# EFR32MG24A420F1536IM48 register map
Vendor: Silicon Labs; Series: EFR32; File version: B
Registers are 32-bit, read-write, reset 0x0 unless marked. A register's access mark holds for its fields unless they carry their own. Offsets are from the block's base; [hi:lo] are bit positions; {n}, {i} and the like mark numbered series.

## DMEM_NS — DMEM_NS Registers
Base 0x500B4000
Same registers: DMEM_S 0x400B4000
0x00 IPVERSION ro reset 0x2
  [1:0] IPVERSION — New BitField
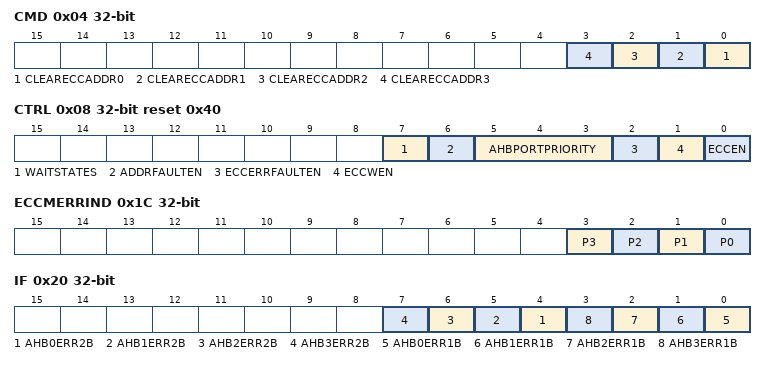
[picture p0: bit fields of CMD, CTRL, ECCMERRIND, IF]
0x04 CMD wo
  [n] CLEARECCADDR{n} (n=0..3) — Clear ECCERRADDR{n}
0x08 CTRL reset 0x40
  [7] WAITSTATES — RAM read wait states
  [6] ADDRFAULTEN — Address fault bus fault enable
  [5:3] AHBPORTPRIORITY — AHB port arbitration priority
    0=NONE (No AHB port have raised priority.); {v}=PORT{v-1} (AHB port {v-1} has raised priority.) (v=1..4)
  [2] ECCERRFAULTEN — ECC Error bus fault enable
  [1] ECCWEN — Enable ECC syndrome writes
  [0] ECCEN — Enable ECC functionality
{0xC+4i} ECCERRADDR{i} ro (i=0..3)
  [31:0] ADDR — ECC Error Address
0x1C ECCMERRIND ro
  [3] P3 — Multiple ECC errors on AHB port 2
  [2] P2 — Multiple ECC errors on AHB port 2
  [1] P1 — Multiple ECC errors on AHB port 1
  [0] P0 — Multiple ECC errors on AHB port 0
0x20 IF
  [n+4] AHB{n}ERR2B (n=0..3) — AHB{n} 2-bit ECC Error Interrupt Flag
  [n] AHB{n}ERR1B (n=0..3) — AHB{n} 1-bit ECC Error Interrupt Flag
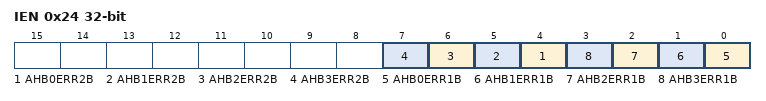
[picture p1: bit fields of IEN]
0x24 IEN
  [n+4] AHB{n}ERR2B (n=0..3) — AHB{n} 2-bit ECC Error Interrupt Enable
  [n] AHB{n}ERR1B (n=0..3) — AHB{n} 1-bit ECC Error Interrupt Enable

## DPLL0_NS — DPLL0_NS Registers
Base 0x5001C000
Same registers: DPLL0_S 0x4001C000
0x00 IPVERSION ro reset 0x1
  [31:0] IPVERSION — IP Version ID
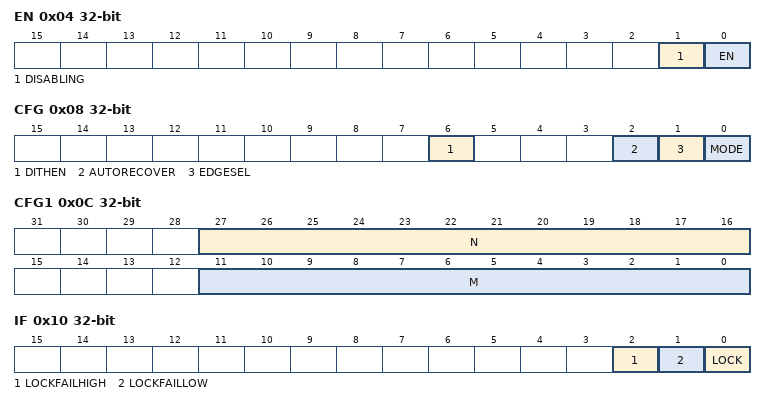
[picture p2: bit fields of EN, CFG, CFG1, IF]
0x04 EN
  [1] DISABLING ro — Disablement Busy Status
  [0] EN — Module Enable
0x08 CFG
  [6] DITHEN — Dither Enable Control
  [2] AUTORECOVER — Automatic Recovery Control
  [1] EDGESEL — Reference Edge Select
  [0] MODE — Operating Mode Control
    0=FLL (Frequency Lock Mode); 1=PLL (Phase Lock Mode)
0x0C CFG1
  [27:16] N — Factor N
  [11:0] M — Factor M
0x10 IF
  [2] LOCKFAILHIGH — Lock Failure High Interrupt Flag
  [1] LOCKFAILLOW — Lock Failure Low Interrupt Flag
  [0] LOCK — Lock Interrupt Flag
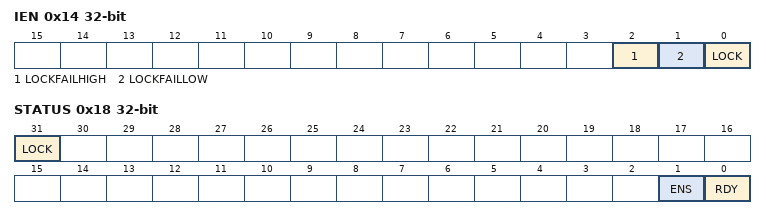
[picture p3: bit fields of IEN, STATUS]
0x14 IEN
  [2] LOCKFAILHIGH — LOCKFAILHIGH Interrupt Enable
  [1] LOCKFAILLOW — LOCKFAILLOW Interrupe Enable
  [0] LOCK — LOCK interrupt Enable
0x18 STATUS ro
  [31] LOCK — Lock Status
    0=UNLOCKED (DPLL is unlocked); 1=LOCKED (DPLL is locked)
  [1] ENS — Enable Status
  [0] RDY — Ready Status
0x24 LOCK wo reset 0x7102
  [15:0] LOCKKEY
    0x7102=UNLOCK (Unlock code)

## FSRCO_NS — FSRCO_NS Registers
Base 0x50018000
Same registers: FSRCO_S 0x40018000
0x00 IPVERSION ro

## GPCRC_NS — GPCRC_NS Registers
Base 0x50088000
Same registers: GPCRC_S 0x40088000
0x00 IPVERSION ro
  [31:0] IPVERSION — IP Version ID
0x04 EN
  [0] EN — CRC Enable
    0=DISABLE (Disable CRC function. Reordering functions are still available. Only BITREVERSE and BYTEREVERSE bits are configurable in this mode.); 1=ENABLE (Writes to INPUTDATA registers will result in CRC operations.)
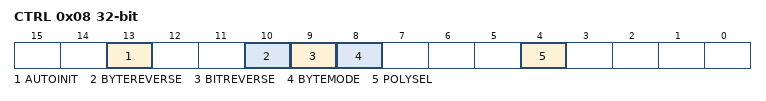
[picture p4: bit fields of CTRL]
0x08 CTRL
  [13] AUTOINIT — Auto Init Enable
  [10] BYTEREVERSE — Byte Reverse Mode
    0=NORMAL (No reverse: B3, B2, B1, B0); 1=REVERSED (Reverse byte order. For 32-bit: B0, B1, B2, B3; For 16-bit: 0, 0, B0, B1)
  [9] BITREVERSE — Byte-level Bit Reverse Enable
    0=NORMAL (No reverse); 1=REVERSED (Reverse bit order in each byte)
  [8] BYTEMODE — Byte Mode Enable
  [4] POLYSEL — Polynomial Select
    0=CRC32 (CRC-32 (0x04C11DB7) polynomial selected); 1=CRC16 (16-bit CRC programmable polynomial selected)
0x0C CMD wo
  [0] INIT — Initialization Enable
0x10 INIT
  [31:0] INIT — CRC Initialization Value
0x14 POLY
  [15:0] POLY — CRC Polynomial Value
0x18 INPUTDATA wo
  [31:0] INPUTDATA — Input Data for 32-bit
0x1C INPUTDATAHWORD wo
  [15:0] INPUTDATAHWORD — Input Data for 16-bit
0x20 INPUTDATABYTE wo
  [7:0] INPUTDATABYTE — Input Data for 8-bit
0x24 DATA ro
  [31:0] DATA — CRC Data Register
0x28 DATAREV ro
  [31:0] DATAREV — Data Reverse Value
0x2C DATABYTEREV ro
  [31:0] DATABYTEREV — Data Byte Reverse Value
